# CBASS0_QOS register map
Vendor: Texas Instruments
Peripheral module from a debugger description file (folder J722S).
Registers are 32-bit, read-write, reset 0x7000 unless marked. A register's access mark holds for its fields unless they carry their own. Offsets are as the file gives them; lines under a group give offsets from that group; [hi:lo] are bit positions; {n}, {i} and the like mark numbered series; 'fields as' and 'values as' point back to an identical list; <NAME> marks a mode.

## CBASS0_QOS
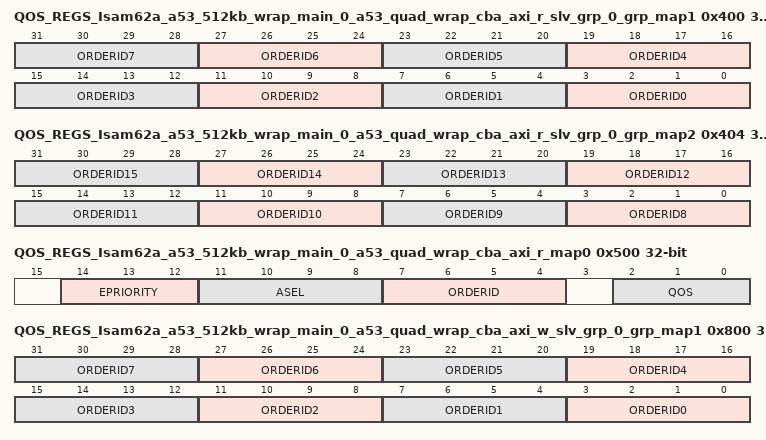
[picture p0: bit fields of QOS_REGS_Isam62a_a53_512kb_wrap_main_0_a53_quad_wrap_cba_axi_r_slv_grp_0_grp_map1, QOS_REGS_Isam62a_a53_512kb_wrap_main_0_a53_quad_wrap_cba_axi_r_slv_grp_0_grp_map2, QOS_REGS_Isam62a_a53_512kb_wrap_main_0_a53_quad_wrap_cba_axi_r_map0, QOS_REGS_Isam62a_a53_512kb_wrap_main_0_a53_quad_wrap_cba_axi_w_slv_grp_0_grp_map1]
0x400 QOS_REGS_Isam62a_a53_512kb_wrap_main_0_a53_quad_wrap_cba_axi_r_slv_grp_0_grp_map1 reset 0x0 — The Group Map Register defines the final orderid for the initiator Isam62a_a53_512kb_wrap_main_0.a53_quad_wrap_cba_axi_r for group slv_grp_0.
  [4n+3:4n] ORDERID{n} (n=0..7) — orderid signal for {n}.
0x404 QOS_REGS_Isam62a_a53_512kb_wrap_main_0_a53_quad_wrap_cba_axi_r_slv_grp_0_grp_map2 reset 0x0 — The Group Map Register defines the final orderid for the initiator Isam62a_a53_512kb_wrap_main_0.a53_quad_wrap_cba_axi_r for group slv_grp_0.
  [4n-29:4n-32] ORDERID{n} (n=8..15) — orderid signal for {n-8}.
0x500 QOS_REGS_Isam62a_a53_512kb_wrap_main_0_a53_quad_wrap_cba_axi_r_map0 — The Map Register defines the fields for the initiator Isam62a_a53_512kb_wrap_main_0.a53_quad_wrap_cba_axi_r per channel.
  [14:12] EPRIORITY — epriority signal for channel N.
  [11:8] ASEL — asel signal for channel N. 0 = SOC address. 1-15 = peripheral address.
  [7:4] ORDERID — orderid signal for channel N.
  [2:0] QOS — qos signal for channel N.
0x800 QOS_REGS_Isam62a_a53_512kb_wrap_main_0_a53_quad_wrap_cba_axi_w_slv_grp_0_grp_map1 reset 0x0 — The Group Map Register defines the final orderid for the initiator Isam62a_a53_512kb_wrap_main_0.a53_quad_wrap_cba_axi_w for group slv_grp_0.
  [4n+3:4n] ORDERID{n} (n=0..7) — orderid signal for {n}.
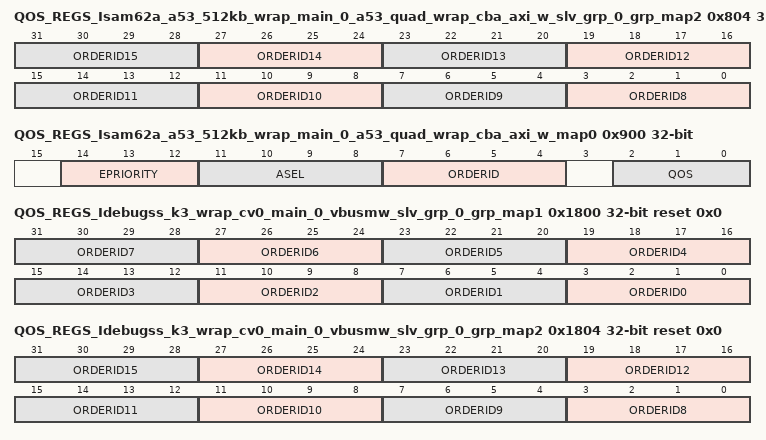
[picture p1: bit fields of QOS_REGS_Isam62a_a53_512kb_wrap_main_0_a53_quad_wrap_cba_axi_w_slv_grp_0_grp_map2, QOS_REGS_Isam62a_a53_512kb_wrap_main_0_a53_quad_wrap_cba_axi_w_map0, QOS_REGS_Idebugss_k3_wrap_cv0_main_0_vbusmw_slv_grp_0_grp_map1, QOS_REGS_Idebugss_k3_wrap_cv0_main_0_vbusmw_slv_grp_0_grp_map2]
0x804 QOS_REGS_Isam62a_a53_512kb_wrap_main_0_a53_quad_wrap_cba_axi_w_slv_grp_0_grp_map2 reset 0x0 — The Group Map Register defines the final orderid for the initiator Isam62a_a53_512kb_wrap_main_0.a53_quad_wrap_cba_axi_w for group slv_grp_0.
  [4n-29:4n-32] ORDERID{n} (n=8..15) — orderid signal for {n-8}.
0x900 QOS_REGS_Isam62a_a53_512kb_wrap_main_0_a53_quad_wrap_cba_axi_w_map0 — The Map Register defines the fields for the initiator Isam62a_a53_512kb_wrap_main_0.a53_quad_wrap_cba_axi_w per channel.
  fields as QOS_REGS_Isam62a_a53_512kb_wrap_main_0_a53_quad_wrap_cba_axi_r_map0
0x1800 QOS_REGS_Idebugss_k3_wrap_cv0_main_0_vbusmw_slv_grp_0_grp_map1 reset 0x0 — The Group Map Register defines the final orderid for the initiator Idebugss_k3_wrap_cv0_main_0.vbusmw for group slv_grp_0.
  [4n+3:4n] ORDERID{n} (n=0..7) — orderid signal for {n}.
0x1804 QOS_REGS_Idebugss_k3_wrap_cv0_main_0_vbusmw_slv_grp_0_grp_map2 reset 0x0 — The Group Map Register defines the final orderid for the initiator Idebugss_k3_wrap_cv0_main_0.vbusmw for group slv_grp_0.
  [4n-29:4n-32] ORDERID{n} (n=8..15) — orderid signal for {n-8}.
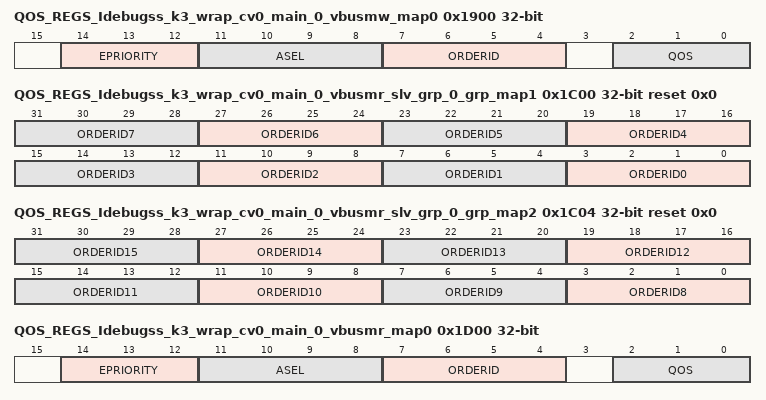
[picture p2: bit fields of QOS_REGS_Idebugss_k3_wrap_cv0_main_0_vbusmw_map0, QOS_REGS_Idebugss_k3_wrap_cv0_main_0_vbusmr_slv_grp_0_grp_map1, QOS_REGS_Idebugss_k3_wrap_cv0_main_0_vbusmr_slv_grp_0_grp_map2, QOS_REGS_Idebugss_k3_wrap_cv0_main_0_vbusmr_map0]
0x1900 QOS_REGS_Idebugss_k3_wrap_cv0_main_0_vbusmw_map0 — The Map Register defines the fields for the initiator Idebugss_k3_wrap_cv0_main_0.vbusmw per channel.
  fields as QOS_REGS_Isam62a_a53_512kb_wrap_main_0_a53_quad_wrap_cba_axi_r_map0
0x1C00 QOS_REGS_Idebugss_k3_wrap_cv0_main_0_vbusmr_slv_grp_0_grp_map1 reset 0x0 — The Group Map Register defines the final orderid for the initiator Idebugss_k3_wrap_cv0_main_0.vbusmr for group slv_grp_0.
  [4n+3:4n] ORDERID{n} (n=0..7) — orderid signal for {n}.
0x1C04 QOS_REGS_Idebugss_k3_wrap_cv0_main_0_vbusmr_slv_grp_0_grp_map2 reset 0x0 — The Group Map Register defines the final orderid for the initiator Idebugss_k3_wrap_cv0_main_0.vbusmr for group slv_grp_0.
  [4n-29:4n-32] ORDERID{n} (n=8..15) — orderid signal for {n-8}.
0x1D00 QOS_REGS_Idebugss_k3_wrap_cv0_main_0_vbusmr_map0 — The Map Register defines the fields for the initiator Idebugss_k3_wrap_cv0_main_0.vbusmr per channel.
  fields as QOS_REGS_Isam62a_a53_512kb_wrap_main_0_a53_quad_wrap_cba_axi_r_map0
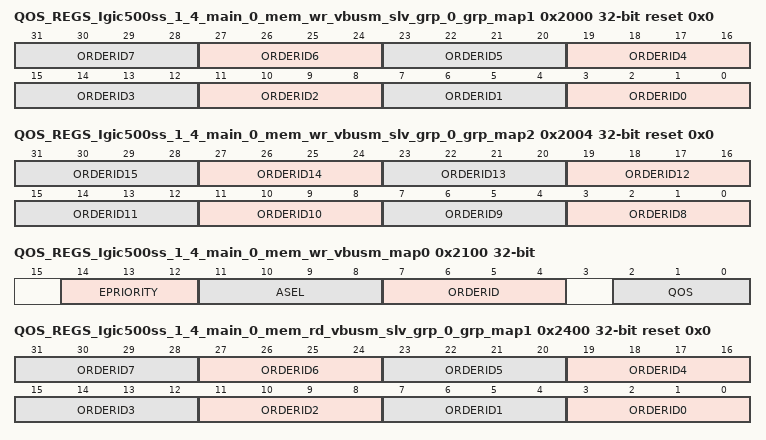
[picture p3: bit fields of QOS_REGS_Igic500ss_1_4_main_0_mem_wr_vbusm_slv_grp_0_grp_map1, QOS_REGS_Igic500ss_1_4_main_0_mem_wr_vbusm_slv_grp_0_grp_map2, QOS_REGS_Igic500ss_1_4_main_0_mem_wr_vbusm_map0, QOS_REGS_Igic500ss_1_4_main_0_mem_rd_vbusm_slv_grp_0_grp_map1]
0x2000 QOS_REGS_Igic500ss_1_4_main_0_mem_wr_vbusm_slv_grp_0_grp_map1 reset 0x0 — The Group Map Register defines the final orderid for the initiator Igic500ss_1_4_main_0.mem_wr_vbusm for group slv_grp_0.
  [4n+3:4n] ORDERID{n} (n=0..7) — orderid signal for {n}.
0x2004 QOS_REGS_Igic500ss_1_4_main_0_mem_wr_vbusm_slv_grp_0_grp_map2 reset 0x0 — The Group Map Register defines the final orderid for the initiator Igic500ss_1_4_main_0.mem_wr_vbusm for group slv_grp_0.
  [4n-29:4n-32] ORDERID{n} (n=8..15) — orderid signal for {n-8}.
0x2100 QOS_REGS_Igic500ss_1_4_main_0_mem_wr_vbusm_map0 — The Map Register defines the fields for the initiator Igic500ss_1_4_main_0.mem_wr_vbusm per channel.
  fields as QOS_REGS_Isam62a_a53_512kb_wrap_main_0_a53_quad_wrap_cba_axi_r_map0
0x2400 QOS_REGS_Igic500ss_1_4_main_0_mem_rd_vbusm_slv_grp_0_grp_map1 reset 0x0 — The Group Map Register defines the final orderid for the initiator Igic500ss_1_4_main_0.mem_rd_vbusm for group slv_grp_0.
  [4n+3:4n] ORDERID{n} (n=0..7) — orderid signal for {n}.
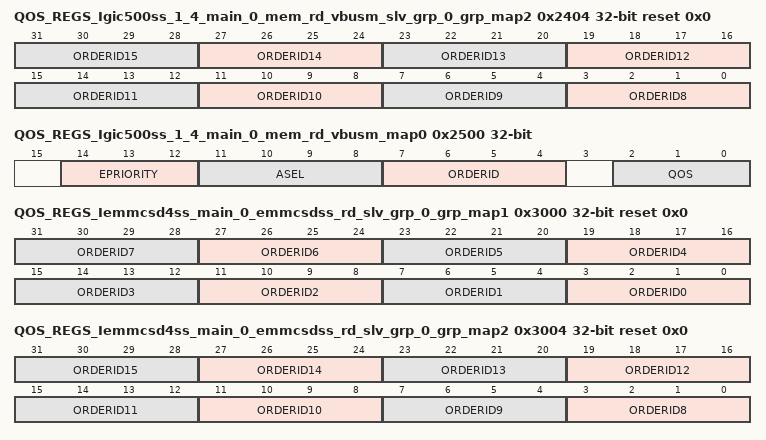
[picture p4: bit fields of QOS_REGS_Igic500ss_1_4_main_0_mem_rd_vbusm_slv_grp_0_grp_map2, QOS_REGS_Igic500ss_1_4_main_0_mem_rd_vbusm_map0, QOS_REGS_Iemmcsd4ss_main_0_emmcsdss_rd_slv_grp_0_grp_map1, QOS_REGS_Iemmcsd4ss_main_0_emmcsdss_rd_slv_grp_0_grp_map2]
0x2404 QOS_REGS_Igic500ss_1_4_main_0_mem_rd_vbusm_slv_grp_0_grp_map2 reset 0x0 — The Group Map Register defines the final orderid for the initiator Igic500ss_1_4_main_0.mem_rd_vbusm for group slv_grp_0.
  [4n-29:4n-32] ORDERID{n} (n=8..15) — orderid signal for {n-8}.
0x2500 QOS_REGS_Igic500ss_1_4_main_0_mem_rd_vbusm_map0 — The Map Register defines the fields for the initiator Igic500ss_1_4_main_0.mem_rd_vbusm per channel.
  fields as QOS_REGS_Isam62a_a53_512kb_wrap_main_0_a53_quad_wrap_cba_axi_r_map0
0x3000 QOS_REGS_Iemmcsd4ss_main_0_emmcsdss_rd_slv_grp_0_grp_map1 reset 0x0 — The Group Map Register defines the final orderid for the initiator Iemmcsd4ss_main_0.emmcsdss_rd for group slv_grp_0.
  [4n+3:4n] ORDERID{n} (n=0..7) — orderid signal for {n}.
0x3004 QOS_REGS_Iemmcsd4ss_main_0_emmcsdss_rd_slv_grp_0_grp_map2 reset 0x0 — The Group Map Register defines the final orderid for the initiator Iemmcsd4ss_main_0.emmcsdss_rd for group slv_grp_0.
  [4n-29:4n-32] ORDERID{n} (n=8..15) — orderid signal for {n-8}.
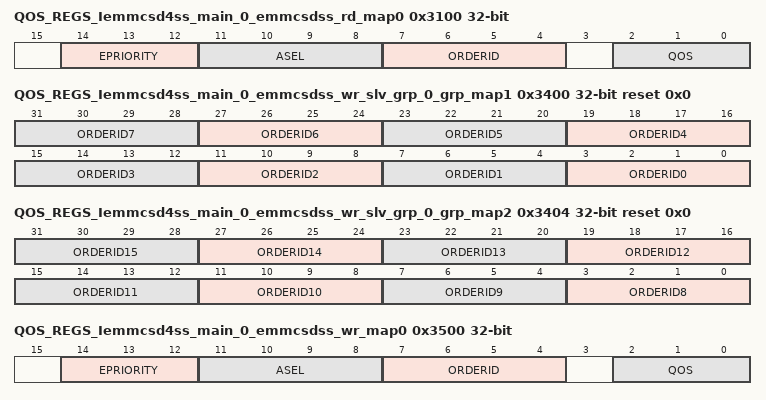
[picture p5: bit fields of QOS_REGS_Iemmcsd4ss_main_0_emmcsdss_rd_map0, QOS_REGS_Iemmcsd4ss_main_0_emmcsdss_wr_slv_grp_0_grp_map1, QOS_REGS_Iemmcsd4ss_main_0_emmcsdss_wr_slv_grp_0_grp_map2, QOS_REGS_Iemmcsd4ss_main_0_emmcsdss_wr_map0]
0x3100 QOS_REGS_Iemmcsd4ss_main_0_emmcsdss_rd_map0 — The Map Register defines the fields for the initiator Iemmcsd4ss_main_0.emmcsdss_rd per channel.
  fields as QOS_REGS_Isam62a_a53_512kb_wrap_main_0_a53_quad_wrap_cba_axi_r_map0
0x3400 QOS_REGS_Iemmcsd4ss_main_0_emmcsdss_wr_slv_grp_0_grp_map1 reset 0x0 — The Group Map Register defines the final orderid for the initiator Iemmcsd4ss_main_0.emmcsdss_wr for group slv_grp_0.
  [4n+3:4n] ORDERID{n} (n=0..7) — orderid signal for {n}.
0x3404 QOS_REGS_Iemmcsd4ss_main_0_emmcsdss_wr_slv_grp_0_grp_map2 reset 0x0 — The Group Map Register defines the final orderid for the initiator Iemmcsd4ss_main_0.emmcsdss_wr for group slv_grp_0.
  [4n-29:4n-32] ORDERID{n} (n=8..15) — orderid signal for {n-8}.
0x3500 QOS_REGS_Iemmcsd4ss_main_0_emmcsdss_wr_map0 — The Map Register defines the fields for the initiator Iemmcsd4ss_main_0.emmcsdss_wr per channel.
  fields as QOS_REGS_Isam62a_a53_512kb_wrap_main_0_a53_quad_wrap_cba_axi_r_map0
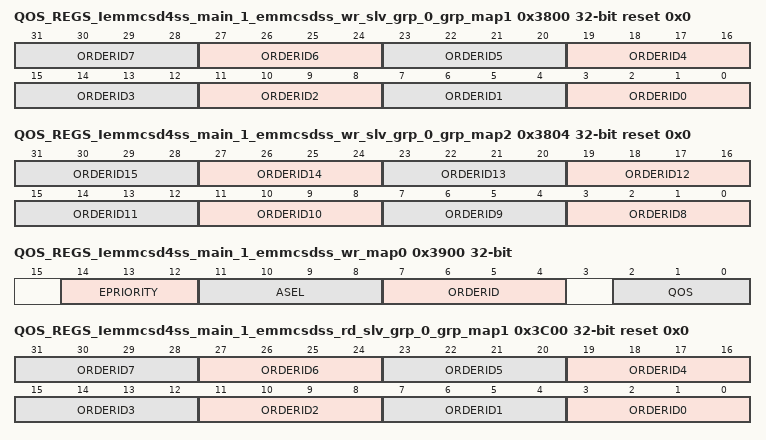
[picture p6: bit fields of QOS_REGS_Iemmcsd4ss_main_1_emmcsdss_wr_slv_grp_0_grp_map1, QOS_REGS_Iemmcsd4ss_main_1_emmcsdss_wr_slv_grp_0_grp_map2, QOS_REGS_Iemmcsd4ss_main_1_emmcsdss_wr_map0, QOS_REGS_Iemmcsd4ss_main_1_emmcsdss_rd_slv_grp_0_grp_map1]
0x3800 QOS_REGS_Iemmcsd4ss_main_1_emmcsdss_wr_slv_grp_0_grp_map1 reset 0x0 — The Group Map Register defines the final orderid for the initiator Iemmcsd4ss_main_1.emmcsdss_wr for group slv_grp_0.
  [4n+3:4n] ORDERID{n} (n=0..7) — orderid signal for {n}.
0x3804 QOS_REGS_Iemmcsd4ss_main_1_emmcsdss_wr_slv_grp_0_grp_map2 reset 0x0 — The Group Map Register defines the final orderid for the initiator Iemmcsd4ss_main_1.emmcsdss_wr for group slv_grp_0.
  [4n-29:4n-32] ORDERID{n} (n=8..15) — orderid signal for {n-8}.
0x3900 QOS_REGS_Iemmcsd4ss_main_1_emmcsdss_wr_map0 — The Map Register defines the fields for the initiator Iemmcsd4ss_main_1.emmcsdss_wr per channel.
  fields as QOS_REGS_Isam62a_a53_512kb_wrap_main_0_a53_quad_wrap_cba_axi_r_map0
0x3C00 QOS_REGS_Iemmcsd4ss_main_1_emmcsdss_rd_slv_grp_0_grp_map1 reset 0x0 — The Group Map Register defines the final orderid for the initiator Iemmcsd4ss_main_1.emmcsdss_rd for group slv_grp_0.
  [4n+3:4n] ORDERID{n} (n=0..7) — orderid signal for {n}.
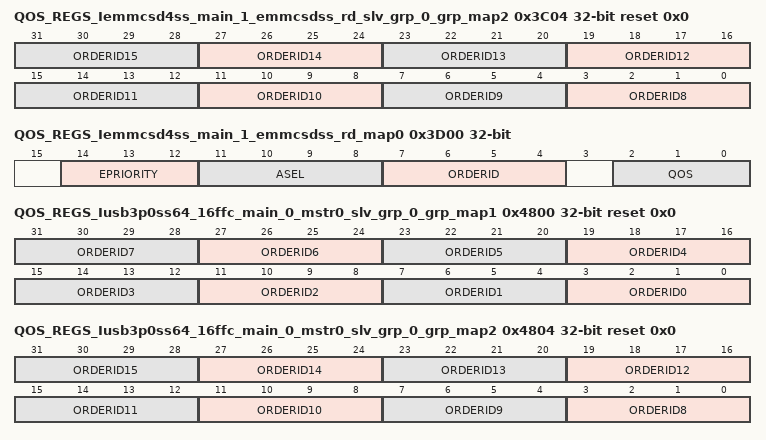
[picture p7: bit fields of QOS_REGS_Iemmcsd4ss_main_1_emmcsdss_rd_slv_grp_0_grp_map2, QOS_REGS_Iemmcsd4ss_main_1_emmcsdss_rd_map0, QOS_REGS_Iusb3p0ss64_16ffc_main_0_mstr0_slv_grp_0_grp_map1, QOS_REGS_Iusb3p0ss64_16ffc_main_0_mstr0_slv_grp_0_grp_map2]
0x3C04 QOS_REGS_Iemmcsd4ss_main_1_emmcsdss_rd_slv_grp_0_grp_map2 reset 0x0 — The Group Map Register defines the final orderid for the initiator Iemmcsd4ss_main_1.emmcsdss_rd for group slv_grp_0.
  [4n-29:4n-32] ORDERID{n} (n=8..15) — orderid signal for {n-8}.
0x3D00 QOS_REGS_Iemmcsd4ss_main_1_emmcsdss_rd_map0 — The Map Register defines the fields for the initiator Iemmcsd4ss_main_1.emmcsdss_rd per channel.
  fields as QOS_REGS_Isam62a_a53_512kb_wrap_main_0_a53_quad_wrap_cba_axi_r_map0
0x4800 QOS_REGS_Iusb3p0ss64_16ffc_main_0_mstr0_slv_grp_0_grp_map1 reset 0x0 — The Group Map Register defines the final orderid for the initiator Iusb3p0ss64_16ffc_main_0.mstr0 for group slv_grp_0.
  [4n+3:4n] ORDERID{n} (n=0..7) — orderid signal for {n}.
0x4804 QOS_REGS_Iusb3p0ss64_16ffc_main_0_mstr0_slv_grp_0_grp_map2 reset 0x0 — The Group Map Register defines the final orderid for the initiator Iusb3p0ss64_16ffc_main_0.mstr0 for group slv_grp_0.
  [4n-29:4n-32] ORDERID{n} (n=8..15) — orderid signal for {n-8}.
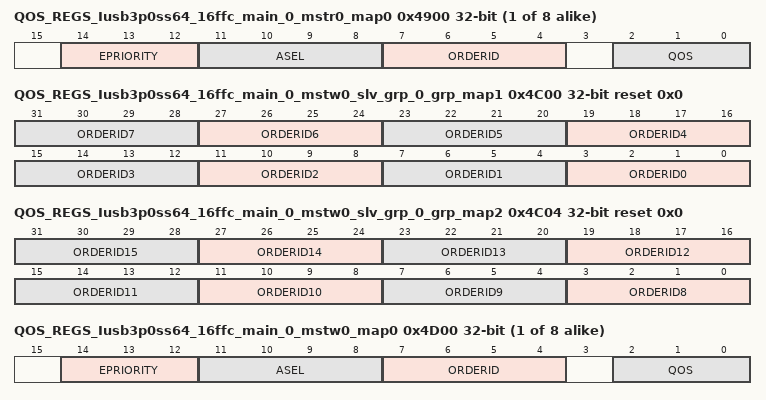
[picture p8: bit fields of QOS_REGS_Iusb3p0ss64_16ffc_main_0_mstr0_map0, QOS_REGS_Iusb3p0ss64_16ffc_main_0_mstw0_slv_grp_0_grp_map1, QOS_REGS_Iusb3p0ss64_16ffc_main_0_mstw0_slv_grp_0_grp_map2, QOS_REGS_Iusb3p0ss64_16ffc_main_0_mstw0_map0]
{0x4900+4i} QOS_REGS_Iusb3p0ss64_16ffc_main_0_mstr0_map{i} (i=0..7) — The Map Register defines the fields for the initiator Iusb3p0ss64_16ffc_main_0.mstr0 per channel.
  fields as QOS_REGS_Isam62a_a53_512kb_wrap_main_0_a53_quad_wrap_cba_axi_r_map0
0x4C00 QOS_REGS_Iusb3p0ss64_16ffc_main_0_mstw0_slv_grp_0_grp_map1 reset 0x0 — The Group Map Register defines the final orderid for the initiator Iusb3p0ss64_16ffc_main_0.mstw0 for group slv_grp_0.
  [4n+3:4n] ORDERID{n} (n=0..7) — orderid signal for {n}.
0x4C04 QOS_REGS_Iusb3p0ss64_16ffc_main_0_mstw0_slv_grp_0_grp_map2 reset 0x0 — The Group Map Register defines the final orderid for the initiator Iusb3p0ss64_16ffc_main_0.mstw0 for group slv_grp_0.
  [4n-29:4n-32] ORDERID{n} (n=8..15) — orderid signal for {n-8}.
{0x4D00+4i} QOS_REGS_Iusb3p0ss64_16ffc_main_0_mstw0_map{i} (i=0..7) — The Map Register defines the fields for the initiator Iusb3p0ss64_16ffc_main_0.mstw0 per channel.
  fields as QOS_REGS_Isam62a_a53_512kb_wrap_main_0_a53_quad_wrap_cba_axi_r_map0
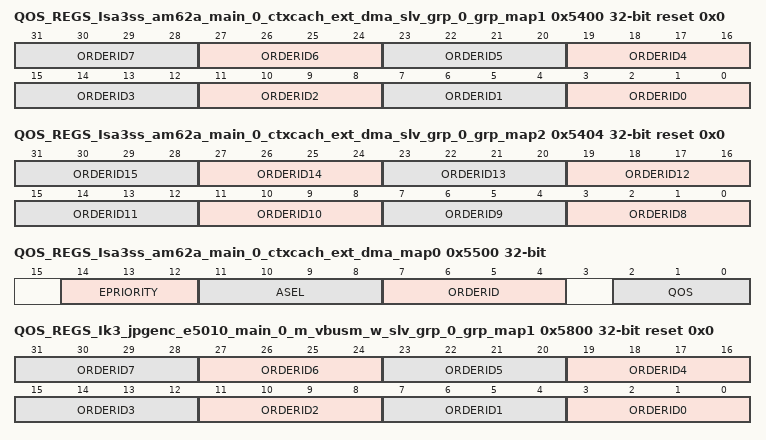
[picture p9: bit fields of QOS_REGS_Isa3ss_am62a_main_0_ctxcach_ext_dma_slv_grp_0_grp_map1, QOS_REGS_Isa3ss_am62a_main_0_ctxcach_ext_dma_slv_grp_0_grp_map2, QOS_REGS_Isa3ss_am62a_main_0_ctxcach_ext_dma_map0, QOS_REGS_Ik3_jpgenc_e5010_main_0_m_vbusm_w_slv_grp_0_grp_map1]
0x5400 QOS_REGS_Isa3ss_am62a_main_0_ctxcach_ext_dma_slv_grp_0_grp_map1 reset 0x0 — The Group Map Register defines the final orderid for the initiator Isa3ss_am62a_main_0.ctxcach_ext_dma for group slv_grp_0.
  [4n+3:4n] ORDERID{n} (n=0..7) — orderid signal for {n}.
0x5404 QOS_REGS_Isa3ss_am62a_main_0_ctxcach_ext_dma_slv_grp_0_grp_map2 reset 0x0 — The Group Map Register defines the final orderid for the initiator Isa3ss_am62a_main_0.ctxcach_ext_dma for group slv_grp_0.
  [4n-29:4n-32] ORDERID{n} (n=8..15) — orderid signal for {n-8}.
0x5500 QOS_REGS_Isa3ss_am62a_main_0_ctxcach_ext_dma_map0 — The Map Register defines the fields for the initiator Isa3ss_am62a_main_0.ctxcach_ext_dma per channel.
  fields as QOS_REGS_Isam62a_a53_512kb_wrap_main_0_a53_quad_wrap_cba_axi_r_map0
0x5800 QOS_REGS_Ik3_jpgenc_e5010_main_0_m_vbusm_w_slv_grp_0_grp_map1 reset 0x0 — The Group Map Register defines the final orderid for the initiator Ik3_jpgenc_e5010_main_0.m_vbusm_w for group slv_grp_0.
  [4n+3:4n] ORDERID{n} (n=0..7) — orderid signal for {n}.
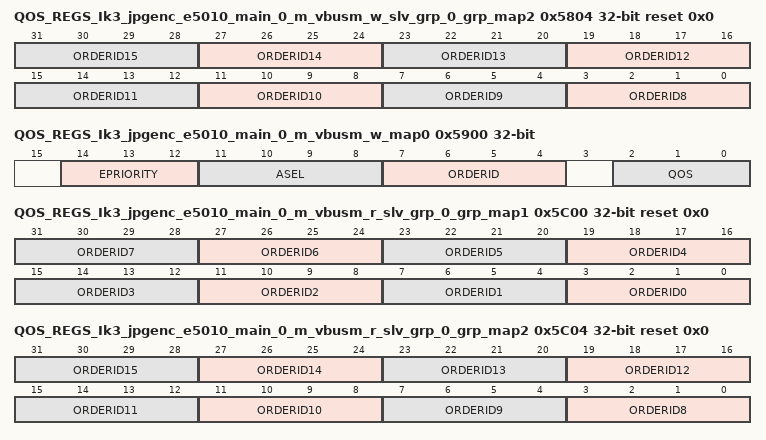
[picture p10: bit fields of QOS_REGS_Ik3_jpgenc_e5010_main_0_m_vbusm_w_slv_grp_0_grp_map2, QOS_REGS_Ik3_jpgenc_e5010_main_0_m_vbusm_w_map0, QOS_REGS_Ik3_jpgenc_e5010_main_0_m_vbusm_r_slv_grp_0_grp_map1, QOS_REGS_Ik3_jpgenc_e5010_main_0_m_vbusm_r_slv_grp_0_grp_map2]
0x5804 QOS_REGS_Ik3_jpgenc_e5010_main_0_m_vbusm_w_slv_grp_0_grp_map2 reset 0x0 — The Group Map Register defines the final orderid for the initiator Ik3_jpgenc_e5010_main_0.m_vbusm_w for group slv_grp_0.
  [4n-29:4n-32] ORDERID{n} (n=8..15) — orderid signal for {n-8}.
0x5900 QOS_REGS_Ik3_jpgenc_e5010_main_0_m_vbusm_w_map0 — The Map Register defines the fields for the initiator Ik3_jpgenc_e5010_main_0.m_vbusm_w per channel.
  fields as QOS_REGS_Isam62a_a53_512kb_wrap_main_0_a53_quad_wrap_cba_axi_r_map0
0x5C00 QOS_REGS_Ik3_jpgenc_e5010_main_0_m_vbusm_r_slv_grp_0_grp_map1 reset 0x0 — The Group Map Register defines the final orderid for the initiator Ik3_jpgenc_e5010_main_0.m_vbusm_r for group slv_grp_0.
  [4n+3:4n] ORDERID{n} (n=0..7) — orderid signal for {n}.
0x5C04 QOS_REGS_Ik3_jpgenc_e5010_main_0_m_vbusm_r_slv_grp_0_grp_map2 reset 0x0 — The Group Map Register defines the final orderid for the initiator Ik3_jpgenc_e5010_main_0.m_vbusm_r for group slv_grp_0.
  [4n-29:4n-32] ORDERID{n} (n=8..15) — orderid signal for {n-8}.
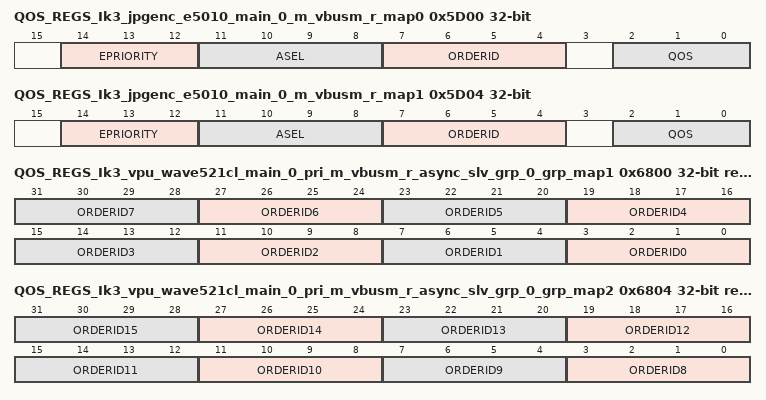
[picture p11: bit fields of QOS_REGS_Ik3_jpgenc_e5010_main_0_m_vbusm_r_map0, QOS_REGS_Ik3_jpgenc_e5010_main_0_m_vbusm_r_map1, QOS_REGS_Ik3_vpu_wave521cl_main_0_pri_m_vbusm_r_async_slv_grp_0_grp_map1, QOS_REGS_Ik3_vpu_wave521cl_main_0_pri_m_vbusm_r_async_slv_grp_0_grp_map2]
0x5D00 QOS_REGS_Ik3_jpgenc_e5010_main_0_m_vbusm_r_map0 — The Map Register defines the fields for the initiator Ik3_jpgenc_e5010_main_0.m_vbusm_r per channel.
  fields as QOS_REGS_Isam62a_a53_512kb_wrap_main_0_a53_quad_wrap_cba_axi_r_map0
0x5D04 QOS_REGS_Ik3_jpgenc_e5010_main_0_m_vbusm_r_map1 — The Map Register defines the fields for the initiator Ik3_jpgenc_e5010_main_0.m_vbusm_r per channel.
  fields as QOS_REGS_Isam62a_a53_512kb_wrap_main_0_a53_quad_wrap_cba_axi_r_map0
0x6800 QOS_REGS_Ik3_vpu_wave521cl_main_0_pri_m_vbusm_r_async_slv_grp_0_grp_map1 reset 0x0 — The Group Map Register defines the final orderid for the initiator Ik3_vpu_wave521cl_main_0.pri_m_vbusm_r_async for group slv_grp_0.
  [4n+3:4n] ORDERID{n} (n=0..7) — orderid signal for {n}.
0x6804 QOS_REGS_Ik3_vpu_wave521cl_main_0_pri_m_vbusm_r_async_slv_grp_0_grp_map2 reset 0x0 — The Group Map Register defines the final orderid for the initiator Ik3_vpu_wave521cl_main_0.pri_m_vbusm_r_async for group slv_grp_0.
  [4n-29:4n-32] ORDERID{n} (n=8..15) — orderid signal for {n-8}.
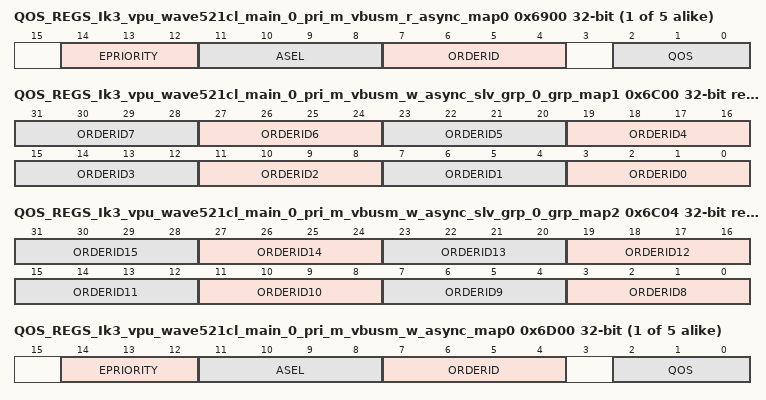
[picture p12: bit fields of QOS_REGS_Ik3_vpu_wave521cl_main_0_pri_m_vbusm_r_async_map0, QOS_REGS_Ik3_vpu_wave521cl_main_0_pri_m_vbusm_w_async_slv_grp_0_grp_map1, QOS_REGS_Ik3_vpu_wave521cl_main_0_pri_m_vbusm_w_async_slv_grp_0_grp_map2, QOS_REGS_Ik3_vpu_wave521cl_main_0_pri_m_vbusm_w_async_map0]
{0x6900+4i} QOS_REGS_Ik3_vpu_wave521cl_main_0_pri_m_vbusm_r_async_map{i} (i=0..4) — The Map Register defines the fields for the initiator Ik3_vpu_wave521cl_main_0.pri_m_vbusm_r_async per channel.
  fields as QOS_REGS_Isam62a_a53_512kb_wrap_main_0_a53_quad_wrap_cba_axi_r_map0
0x6C00 QOS_REGS_Ik3_vpu_wave521cl_main_0_pri_m_vbusm_w_async_slv_grp_0_grp_map1 reset 0x0 — The Group Map Register defines the final orderid for the initiator Ik3_vpu_wave521cl_main_0.pri_m_vbusm_w_async for group slv_grp_0.
  [4n+3:4n] ORDERID{n} (n=0..7) — orderid signal for {n}.
0x6C04 QOS_REGS_Ik3_vpu_wave521cl_main_0_pri_m_vbusm_w_async_slv_grp_0_grp_map2 reset 0x0 — The Group Map Register defines the final orderid for the initiator Ik3_vpu_wave521cl_main_0.pri_m_vbusm_w_async for group slv_grp_0.
  [4n-29:4n-32] ORDERID{n} (n=8..15) — orderid signal for {n-8}.
{0x6D00+4i} QOS_REGS_Ik3_vpu_wave521cl_main_0_pri_m_vbusm_w_async_map{i} (i=0..4) — The Map Register defines the fields for the initiator Ik3_vpu_wave521cl_main_0.pri_m_vbusm_w_async per channel.
  fields as QOS_REGS_Isam62a_a53_512kb_wrap_main_0_a53_quad_wrap_cba_axi_r_map0
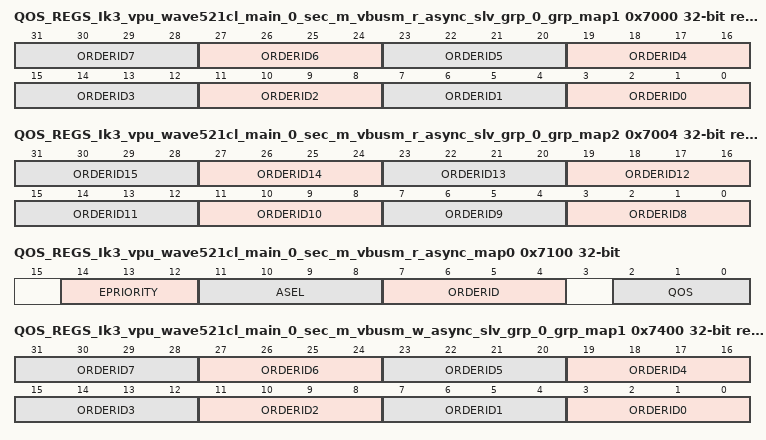
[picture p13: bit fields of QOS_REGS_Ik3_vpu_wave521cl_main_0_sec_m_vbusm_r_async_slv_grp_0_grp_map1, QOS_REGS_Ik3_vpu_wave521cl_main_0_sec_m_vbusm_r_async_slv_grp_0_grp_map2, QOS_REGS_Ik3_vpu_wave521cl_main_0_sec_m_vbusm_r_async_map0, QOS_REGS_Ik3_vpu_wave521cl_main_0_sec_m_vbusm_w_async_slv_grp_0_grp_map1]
0x7000 QOS_REGS_Ik3_vpu_wave521cl_main_0_sec_m_vbusm_r_async_slv_grp_0_grp_map1 reset 0x0 — The Group Map Register defines the final orderid for the initiator Ik3_vpu_wave521cl_main_0.sec_m_vbusm_r_async for group slv_grp_0.
  [4n+3:4n] ORDERID{n} (n=0..7) — orderid signal for {n}.
0x7004 QOS_REGS_Ik3_vpu_wave521cl_main_0_sec_m_vbusm_r_async_slv_grp_0_grp_map2 reset 0x0 — The Group Map Register defines the final orderid for the initiator Ik3_vpu_wave521cl_main_0.sec_m_vbusm_r_async for group slv_grp_0.
  [4n-29:4n-32] ORDERID{n} (n=8..15) — orderid signal for {n-8}.
0x7100 QOS_REGS_Ik3_vpu_wave521cl_main_0_sec_m_vbusm_r_async_map0 — The Map Register defines the fields for the initiator Ik3_vpu_wave521cl_main_0.sec_m_vbusm_r_async per channel.
  fields as QOS_REGS_Isam62a_a53_512kb_wrap_main_0_a53_quad_wrap_cba_axi_r_map0
0x7400 QOS_REGS_Ik3_vpu_wave521cl_main_0_sec_m_vbusm_w_async_slv_grp_0_grp_map1 reset 0x0 — The Group Map Register defines the final orderid for the initiator Ik3_vpu_wave521cl_main_0.sec_m_vbusm_w_async for group slv_grp_0.
  [4n+3:4n] ORDERID{n} (n=0..7) — orderid signal for {n}.
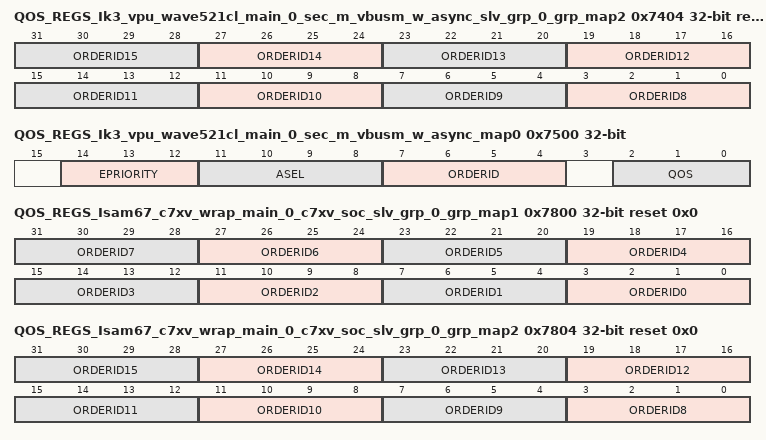
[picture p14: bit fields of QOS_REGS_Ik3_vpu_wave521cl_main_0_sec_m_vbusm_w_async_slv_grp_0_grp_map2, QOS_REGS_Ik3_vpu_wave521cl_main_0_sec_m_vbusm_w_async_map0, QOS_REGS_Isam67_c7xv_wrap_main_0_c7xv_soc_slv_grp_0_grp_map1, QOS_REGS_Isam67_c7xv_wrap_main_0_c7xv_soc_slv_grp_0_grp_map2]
0x7404 QOS_REGS_Ik3_vpu_wave521cl_main_0_sec_m_vbusm_w_async_slv_grp_0_grp_map2 reset 0x0 — The Group Map Register defines the final orderid for the initiator Ik3_vpu_wave521cl_main_0.sec_m_vbusm_w_async for group slv_grp_0.
  [4n-29:4n-32] ORDERID{n} (n=8..15) — orderid signal for {n-8}.
0x7500 QOS_REGS_Ik3_vpu_wave521cl_main_0_sec_m_vbusm_w_async_map0 — The Map Register defines the fields for the initiator Ik3_vpu_wave521cl_main_0.sec_m_vbusm_w_async per channel.
  fields as QOS_REGS_Isam62a_a53_512kb_wrap_main_0_a53_quad_wrap_cba_axi_r_map0
0x7800 QOS_REGS_Isam67_c7xv_wrap_main_0_c7xv_soc_slv_grp_0_grp_map1 reset 0x0 — The Group Map Register defines the final orderid for the initiator Isam67_c7xv_wrap_main_0.c7xv_soc for group slv_grp_0.
  [4n+3:4n] ORDERID{n} (n=0..7) — orderid signal for {n}.
0x7804 QOS_REGS_Isam67_c7xv_wrap_main_0_c7xv_soc_slv_grp_0_grp_map2 reset 0x0 — The Group Map Register defines the final orderid for the initiator Isam67_c7xv_wrap_main_0.c7xv_soc for group slv_grp_0.
  [4n-29:4n-32] ORDERID{n} (n=8..15) — orderid signal for {n-8}.
0x7900 QOS_REGS_Isam67_c7xv_wrap_main_0_c7xv_soc_map0 reset 0x0 — The Map Register defines the fields for the initiator Isam67_c7xv_wrap_main_0.c7xv_soc per channel.
  [7:4] ORDERID — orderid signal for channel N.
  [2:0] QOS — qos signal for channel N.
0x7904 QOS_REGS_Isam67_c7xv_wrap_main_0_c7xv_soc_map1 reset 0x0 — The Map Register defines the fields for the initiator Isam67_c7xv_wrap_main_0.c7xv_soc per channel.
  fields as QOS_REGS_Isam67_c7xv_wrap_main_0_c7xv_soc_map0
0x8000 QOS_REGS_Isam67_vpac_wrap_main_0_ldc0_m_mst_slv_grp_0_grp_map1 reset 0x0 — The Group Map Register defines the final orderid for the initiator Isam67_vpac_wrap_main_0.ldc0_m_mst for group slv_grp_0.
  [4n+3:4n] ORDERID{n} (n=0..7) — orderid signal for {n}.
0x8004 QOS_REGS_Isam67_vpac_wrap_main_0_ldc0_m_mst_slv_grp_0_grp_map2 reset 0x0 — The Group Map Register defines the final orderid for the initiator Isam67_vpac_wrap_main_0.ldc0_m_mst for group slv_grp_0.
  [4n-29:4n-32] ORDERID{n} (n=8..15) — orderid signal for {n-8}.
{0x8100+4i} QOS_REGS_Isam67_vpac_wrap_main_0_ldc0_m_mst_map{i} (i=0..2) — The Map Register defines the fields for the initiator Isam67_vpac_wrap_main_0.ldc0_m_mst per channel.
  fields as QOS_REGS_Isam62a_a53_512kb_wrap_main_0_a53_quad_wrap_cba_axi_r_map0
0x9000 QOS_REGS_Ipcie_g2x1_64_main_0_pcie_mst_rd_slv_grp_0_grp_map1 reset 0x0 — The Group Map Register defines the final orderid for the initiator Ipcie_g2x1_64_main_0.pcie_mst_rd for group slv_grp_0.
  [4n+3:4n] ORDERID{n} (n=0..7) — orderid signal for {n}.
0x9004 QOS_REGS_Ipcie_g2x1_64_main_0_pcie_mst_rd_slv_grp_0_grp_map2 reset 0x0 — The Group Map Register defines the final orderid for the initiator Ipcie_g2x1_64_main_0.pcie_mst_rd for group slv_grp_0.
  [4n-29:4n-32] ORDERID{n} (n=8..15) — orderid signal for {n-8}.
{0x9100+4i} QOS_REGS_Ipcie_g2x1_64_main_0_pcie_mst_rd_map{i} (i=0..7) — The Map Register defines the fields for the initiator Ipcie_g2x1_64_main_0.pcie_mst_rd per channel.
  fields as QOS_REGS_Isam62a_a53_512kb_wrap_main_0_a53_quad_wrap_cba_axi_r_map0
0x9400 QOS_REGS_Ipcie_g2x1_64_main_0_pcie_mst_wr_slv_grp_0_grp_map1 reset 0x0 — The Group Map Register defines the final orderid for the initiator Ipcie_g2x1_64_main_0.pcie_mst_wr for group slv_grp_0.
  [4n+3:4n] ORDERID{n} (n=0..7) — orderid signal for {n}.
0x9404 QOS_REGS_Ipcie_g2x1_64_main_0_pcie_mst_wr_slv_grp_0_grp_map2 reset 0x0 — The Group Map Register defines the final orderid for the initiator Ipcie_g2x1_64_main_0.pcie_mst_wr for group slv_grp_0.
  [4n-29:4n-32] ORDERID{n} (n=8..15) — orderid signal for {n-8}.
{0x9500+4i} QOS_REGS_Ipcie_g2x1_64_main_0_pcie_mst_wr_map{i} (i=0..7) — The Map Register defines the fields for the initiator Ipcie_g2x1_64_main_0.pcie_mst_wr per channel.
  fields as QOS_REGS_Isam62a_a53_512kb_wrap_main_0_a53_quad_wrap_cba_axi_r_map0
0x9800 QOS_REGS_Isam67_gpu_bxs464_wrap_main_0_m_vbusm_w_sync_slv_grp_0_grp_map1 reset 0x0 — The Group Map Register defines the final orderid for the initiator Isam67_gpu_bxs464_wrap_main_0.m_vbusm_w_sync for group slv_grp_0.
  [4n+3:4n] ORDERID{n} (n=0..7) — orderid signal for {n}.
0x9804 QOS_REGS_Isam67_gpu_bxs464_wrap_main_0_m_vbusm_w_sync_slv_grp_0_grp_map2 reset 0x0 — The Group Map Register defines the final orderid for the initiator Isam67_gpu_bxs464_wrap_main_0.m_vbusm_w_sync for group slv_grp_0.
  [4n-29:4n-32] ORDERID{n} (n=8..15) — orderid signal for {n-8}.
{0x9900+4i} QOS_REGS_Isam67_gpu_bxs464_wrap_main_0_m_vbusm_w_sync_map{i} (i=0..31) — The Map Register defines the fields for the initiator Isam67_gpu_bxs464_wrap_main_0.m_vbusm_w_sync per channel.
  fields as QOS_REGS_Isam62a_a53_512kb_wrap_main_0_a53_quad_wrap_cba_axi_r_map0
0xA000 QOS_REGS_Isam67_gpu_bxs464_wrap_main_0_m_vbusm_r_sync_slv_grp_0_grp_map1 reset 0x0 — The Group Map Register defines the final orderid for the initiator Isam67_gpu_bxs464_wrap_main_0.m_vbusm_r_sync for group slv_grp_0.
  [4n+3:4n] ORDERID{n} (n=0..7) — orderid signal for {n}.
0xA004 QOS_REGS_Isam67_gpu_bxs464_wrap_main_0_m_vbusm_r_sync_slv_grp_0_grp_map2 reset 0x0 — The Group Map Register defines the final orderid for the initiator Isam67_gpu_bxs464_wrap_main_0.m_vbusm_r_sync for group slv_grp_0.
  [4n-29:4n-32] ORDERID{n} (n=8..15) — orderid signal for {n-8}.
{0xA100+4i} QOS_REGS_Isam67_gpu_bxs464_wrap_main_0_m_vbusm_r_sync_map{i} (i=0..31) — The Map Register defines the fields for the initiator Isam67_gpu_bxs464_wrap_main_0.m_vbusm_r_sync per channel.
  fields as QOS_REGS_Isam62a_a53_512kb_wrap_main_0_a53_quad_wrap_cba_axi_r_map0
0xC000 QOS_REGS_Isam67_c7xv_wrap_main_1_c7xv_soc_slv_grp_0_grp_map1 reset 0x0 — The Group Map Register defines the final orderid for the initiator Isam67_c7xv_wrap_main_1.c7xv_soc for group slv_grp_0.
  [4n+3:4n] ORDERID{n} (n=0..7) — orderid signal for {n}.
0xC004 QOS_REGS_Isam67_c7xv_wrap_main_1_c7xv_soc_slv_grp_0_grp_map2 reset 0x0 — The Group Map Register defines the final orderid for the initiator Isam67_c7xv_wrap_main_1.c7xv_soc for group slv_grp_0.
  [4n-29:4n-32] ORDERID{n} (n=8..15) — orderid signal for {n-8}.
0xC100 QOS_REGS_Isam67_c7xv_wrap_main_1_c7xv_soc_map0 reset 0x0 — The Map Register defines the fields for the initiator Isam67_c7xv_wrap_main_1.c7xv_soc per channel.
  fields as QOS_REGS_Isam67_c7xv_wrap_main_0_c7xv_soc_map0
0xC104 QOS_REGS_Isam67_c7xv_wrap_main_1_c7xv_soc_map1 reset 0x0 — The Map Register defines the fields for the initiator Isam67_c7xv_wrap_main_1.c7xv_soc per channel.
  fields as QOS_REGS_Isam67_c7xv_wrap_main_0_c7xv_soc_map0
